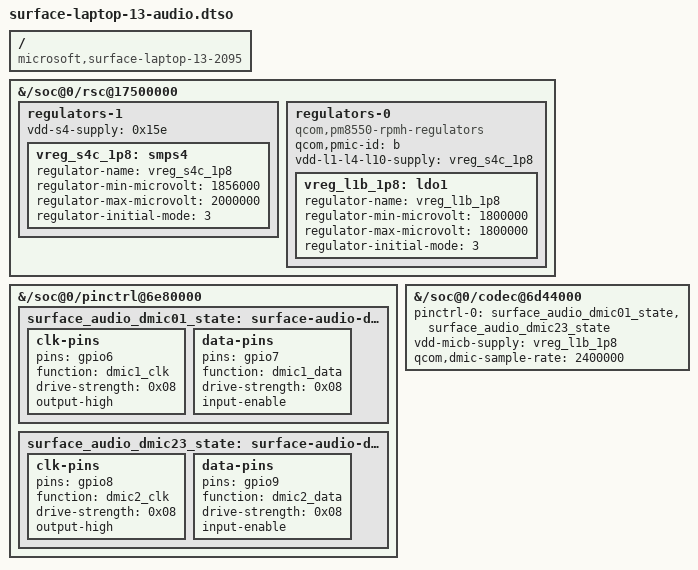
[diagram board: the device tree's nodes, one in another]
/dts-v1/;
/plugin/;

/*
 * Surface Laptop 13 audio fixups.
 *
 * The measured DTB contains the X1E LPASS VA macro and the two WSA884x
 * speakers, but omits the PM8550-B microphone-bias regulator and the LPASS
 * DMIC pinctrl states.  The VA macro consequently falls back to a dummy
 * vdd-micb regulator and the DMIC pins remain in their boot configuration.
 * The 2.4 MHz clock is also required by the known-good X1-family DMIC
 * configuration; 4.8 MHz produces a practically silent capture stream on
 * this machine.
 *
 * The codec's references to existing DMIC states and the microphone-bias
 * regulator are filled by build.sh after the overlay is applied.  This keeps
 * the overlay usable with both the source base DTS and a measured DTB, whose
 * symbols/phandle numbering may differ.
 */

/ {
	compatible = "microsoft,surface-laptop-13-2095", "qcom,x1p42100";

	fragment@0 {
		target-path = "/soc@0/rsc@17500000";
		__overlay__ {
			/* PMC8380C supplies the 1.8 V input used by PM8550-B LDO1. */
			regulators-1 {
				vdd-s4-supply = <0x15e>;

				vreg_s4c_1p8: smps4 {
					regulator-name = "vreg_s4c_1p8";
					regulator-min-microvolt = <1856000>;
					regulator-max-microvolt = <2000000>;
					regulator-initial-mode = <3>;
				};
			};

			/* PM8550-B LDO1 is the VA macro microphone-bias rail. */
			regulators-0 {
				compatible = "qcom,pm8550-rpmh-regulators";
				qcom,pmic-id = "b";
				vdd-l1-l4-l10-supply = <&vreg_s4c_1p8>;

				vreg_l1b_1p8: ldo1 {
					regulator-name = "vreg_l1b_1p8";
					regulator-min-microvolt = <1800000>;
					regulator-max-microvolt = <1800000>;
					regulator-initial-mode = <3>;
				};
			};
		};
	};

	fragment@1 {
		target-path = "/soc@0/pinctrl@6e80000";
		__overlay__ {
			/* Keep these states private to this overlay so no base-DTB
			 * phandle or symbol is required. */
			surface_audio_dmic01_state: surface-audio-dmic01-state {
				clk-pins {
					pins = "gpio6";
					function = "dmic1_clk";
					drive-strength = <0x08>;
					output-high;
				};

				data-pins {
					pins = "gpio7";
					function = "dmic1_data";
					drive-strength = <0x08>;
					input-enable;
				};
			};

			surface_audio_dmic23_state: surface-audio-dmic23-state {
				clk-pins {
					pins = "gpio8";
					function = "dmic2_clk";
					drive-strength = <0x08>;
					output-high;
				};

				data-pins {
					pins = "gpio9";
					function = "dmic2_data";
					drive-strength = <0x08>;
					input-enable;
				};
			};
		};
	};

	fragment@2 {
		target-path = "/soc@0/codec@6d44000";
		__overlay__ {
			pinctrl-0 = <&surface_audio_dmic01_state
					&surface_audio_dmic23_state>;
			pinctrl-names = "default";
			vdd-micb-supply = <&vreg_l1b_1p8>;
			qcom,dmic-sample-rate = <2400000>;
		};
	};
};
